# ATSAMA5D35 register map
Vendor: Atmel; Series: SAMA5D3; File version: 20130221
Registers are 32-bit, read-write, reset 0x0 unless marked. A register's access mark holds for its fields unless they carry their own. Offsets are from the block's base; [hi:lo] are bit positions; {n}, {i} and the like mark numbered series; 'fields as' and 'values as' point back to an identical list.

## AXIMX — AXI Matrix
Base 0x00800000; register names take the prefix AXIMX_
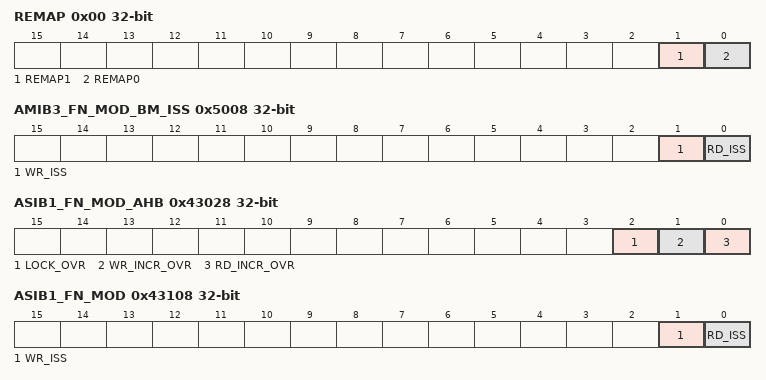
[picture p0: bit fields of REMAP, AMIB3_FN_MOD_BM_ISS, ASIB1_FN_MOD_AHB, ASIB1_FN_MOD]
0x00 REMAP wo
  [1] REMAP1 — Remap State 1
  [0] REMAP0 — Remap State 0
0x1FD0 PERIPH_ID4 ro reset 0x4 — Peripheral ID Register 4
  [7:0] ID — Peripheral ID
    1=Part Number; 4=4KB count, JEP106 continuation code; 179=JEP106[3:0, part number[11:8]; 182=Revision, JEP106 code flag, JEP106[6:4]
{0x1FC0+4i} PERIPH_ID{i} ro (i=5..7) — Peripheral ID Register {i}
  fields as PERIPH_ID4
0x1FE0 PERIPH_ID0 ro reset 0x1 — Peripheral ID Register 0
  fields as PERIPH_ID4
0x1FE4 PERIPH_ID1 ro reset 0xB3 — Peripheral ID Register 1
  fields as PERIPH_ID4
0x1FE8 PERIPH_ID2 ro reset 0x6B — Peripheral ID Register 2
  fields as PERIPH_ID4
0x1FEC PERIPH_ID3 ro — Peripheral ID Register 3
  fields as PERIPH_ID4
{0x1FF0+4i} COMP_ID[{i}] (i=0..3) ro reset not defined — Component ID Register
  [7:0] ID — Component ID
0x5008 AMIB3_FN_MOD_BM_ISS — AMIB3 Bus Matrix Functionality Modification Register
  [1] WR_ISS — Write Issuing
  [0] RD_ISS — Read Issuing
0x5024 AMIB3_FN_MOD2 — AMIB3 Bypass Merge
  [0] BP_MRG — Bypass Merge
0x42100 ASIB0_READ_QOS — ASIB0 Read Channel QoS Register
  [3:0] RD_QOS — Read QoS
0x42104 ASIB0_WRITE_QOS — ASIB0 Write Channel QoS Register
  [3:0] WR_QOS — Write QoS
0x43028 ASIB1_FN_MOD_AHB — ASIB1 AHB Functionality Modification Register
  [2] LOCK_OVR — Lock Override
  [1] WR_INCR_OVR — Write INCR override
  [0] RD_INCR_OVR — Read INCR Override
0x43100 ASIB1_READ_QOS — ASIB1 Read Channel QoS Register
  [3:0] RD_QOS — Read QoS
0x43104 ASIB1_WRITE_QOS — ASIB1 Write Channel QoS Register
  [3:0] WR_QOS — Write QoS
0x43108 ASIB1_FN_MOD — ASIB1 Issuing Functionality Modification Register
  [1] WR_ISS — Write Issuing
  [0] RD_ISS — Read Issuing

## SPI0 — Serial Peripheral Interface 0
Base 0xF0004000; register names take the prefix SPI0_
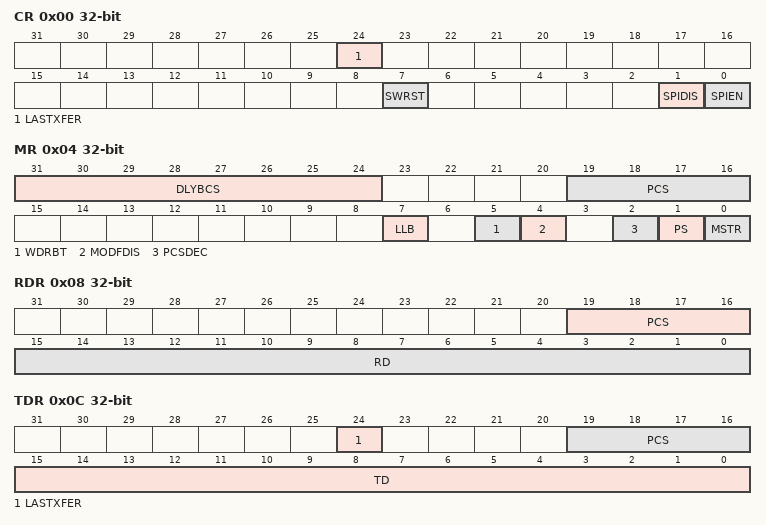
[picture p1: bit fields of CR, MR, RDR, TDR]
0x00 CR wo reset not defined — Control Register
  [24] LASTXFER — Last Transfer
  [7] SWRST — SPI Software Reset
  [1] SPIDIS — SPI Disable
  [0] SPIEN — SPI Enable
0x04 MR — Mode Register
  [31:24] DLYBCS — Delay Between Chip Selects
  [19:16] PCS — Peripheral Chip Select
  [7] LLB — Local Loopback Enable
  [5] WDRBT — Wait Data Read Before Transfer
  [4] MODFDIS — Mode Fault Detection
  [2] PCSDEC — Chip Select Decode
  [1] PS — Peripheral Select
  [0] MSTR — Master/Slave Mode
0x08 RDR ro — Receive Data Register
  [19:16] PCS — Peripheral Chip Select
  [15:0] RD — Receive Data
0x0C TDR wo reset not defined — Transmit Data Register
  [24] LASTXFER — Last Transfer
  [19:16] PCS — Peripheral Chip Select
  [15:0] TD — Transmit Data
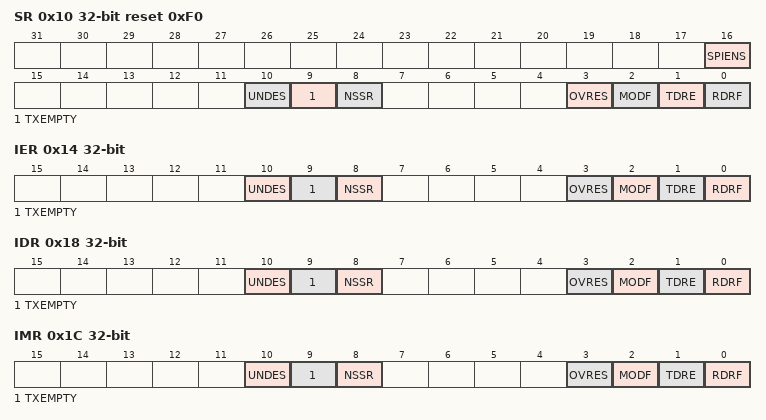
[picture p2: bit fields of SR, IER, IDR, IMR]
0x10 SR ro reset 0xF0 — Status Register
  [16] SPIENS — SPI Enable Status
  [10] UNDES — Underrun Error Status (Slave Mode Only)
  [9] TXEMPTY — Transmission Registers Empty
  [8] NSSR — NSS Rising
  [3] OVRES — Overrun Error Status
  [2] MODF — Mode Fault Error
  [1] TDRE — Transmit Data Register Empty
  [0] RDRF — Receive Data Register Full
0x14 IER wo reset not defined — Interrupt Enable Register
  [10] UNDES — Underrun Error Interrupt Enable
  [9] TXEMPTY — Transmission Registers Empty Enable
  [8] NSSR — NSS Rising Interrupt Enable
  [3] OVRES — Overrun Error Interrupt Enable
  [2] MODF — Mode Fault Error Interrupt Enable
  [1] TDRE — SPI Transmit Data Register Empty Interrupt Enable
  [0] RDRF — Receive Data Register Full Interrupt Enable
0x18 IDR wo reset not defined — Interrupt Disable Register
  [10] UNDES — Underrun Error Interrupt Disable
  [9] TXEMPTY — Transmission Registers Empty Disable
  [8] NSSR — NSS Rising Interrupt Disable
  [3] OVRES — Overrun Error Interrupt Disable
  [2] MODF — Mode Fault Error Interrupt Disable
  [1] TDRE — SPI Transmit Data Register Empty Interrupt Disable
  [0] RDRF — Receive Data Register Full Interrupt Disable
0x1C IMR ro — Interrupt Mask Register
  [10] UNDES — Underrun Error Interrupt Mask
  [9] TXEMPTY — Transmission Registers Empty Mask
  [8] NSSR — NSS Rising Interrupt Mask
  [3] OVRES — Overrun Error Interrupt Mask
  [2] MODF — Mode Fault Error Interrupt Mask
  [1] TDRE — SPI Transmit Data Register Empty Interrupt Mask
  [0] RDRF — Receive Data Register Full Interrupt Mask
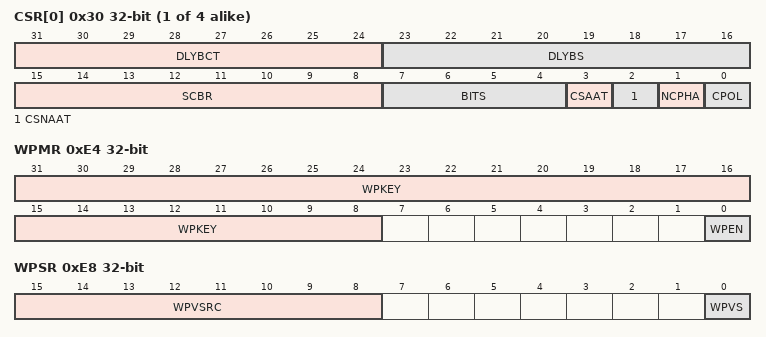
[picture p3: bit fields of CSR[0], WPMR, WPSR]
{0x30+4i} CSR[{i}] (i=0..3) reset not defined — Chip Select Register
  [31:24] DLYBCT — Delay Between Consecutive Transfers
  [23:16] DLYBS — Delay Before SPCK
  [15:8] SCBR — Serial Clock Baud Rate
  [7:4] BITS — Bits Per Transfer
    {v}={v+8}_BIT ({v+8} bits for transfer) (v=0..8)
  [3] CSAAT — Chip Select Active After Transfer
  [2] CSNAAT — Chip Select Not Active After Transfer (Ignored if CSAAT = 1)
  [1] NCPHA — Clock Phase
  [0] CPOL — Clock Polarity
0xE4 WPMR — Write Protection Control Register
  [31:8] WPKEY — Write Protection Key Password
  [0] WPEN — Write Protection Enable
0xE8 WPSR ro — Write Protection Status Register
  [15:8] WPVSRC — Write Protection Violation Source
  [0] WPVS — Write Protection Violation Status

## SPI1 — Serial Peripheral Interface 1
Base 0xF8008000; register names take the prefix SPI1_
Registers as SPI0.
